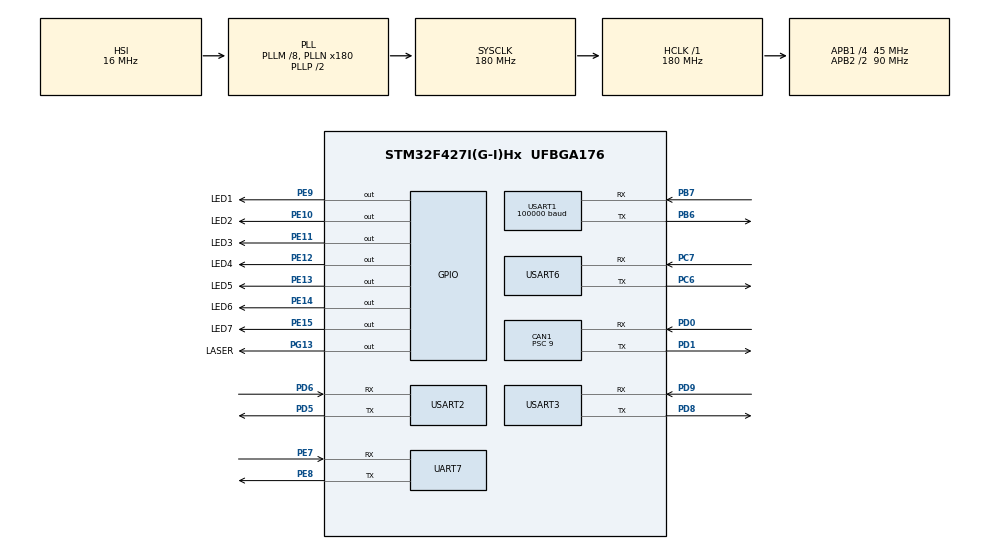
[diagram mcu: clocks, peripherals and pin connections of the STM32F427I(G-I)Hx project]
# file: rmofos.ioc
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CAN1.BS1=CAN_BS1_2TQ
CAN1.BS2=CAN_BS2_2TQ
CAN1.CalculateTimeQuantum=200.0
CAN1.Prescaler=9
CAN1.SJW=CAN_SJW_4TQ
Dma.Request0=USART6_RX
Dma.Request1=USART1_RX
Dma.USART1_RX.1.Direction=DMA_PERIPH_TO_MEMORY
Dma.USART1_RX.1.FIFOMode=DMA_FIFOMODE_DISABLE
Dma.USART1_RX.1.Instance=DMA2_Stream2
Dma.USART1_RX.1.MemDataAlignment=DMA_MDATAALIGN_BYTE
Dma.USART1_RX.1.MemInc=DMA_MINC_ENABLE
Dma.USART1_RX.1.Mode=DMA_NORMAL
Dma.USART1_RX.1.PeriphDataAlignment=DMA_PDATAALIGN_BYTE
Dma.USART1_RX.1.PeriphInc=DMA_PINC_DISABLE
Dma.USART1_RX.1.Priority=DMA_PRIORITY_HIGH
Dma.USART6_RX.0.Direction=DMA_PERIPH_TO_MEMORY
Dma.USART6_RX.0.FIFOMode=DMA_FIFOMODE_DISABLE
Dma.USART6_RX.0.Instance=DMA2_Stream1
Dma.USART6_RX.0.MemDataAlignment=DMA_MDATAALIGN_BYTE
Dma.USART6_RX.0.MemInc=DMA_MINC_ENABLE
Dma.USART6_RX.0.Mode=DMA_NORMAL
Dma.USART6_RX.0.PeriphDataAlignment=DMA_PDATAALIGN_BYTE
Dma.USART6_RX.0.PeriphInc=DMA_PINC_DISABLE
Dma.USART6_RX.0.Priority=DMA_PRIORITY_MEDIUM
FREERTOS.Tasks01=defaultTask,0,128,StartDefaultTask,Default,NULL
FREERTOS.configGENERATE_RUN_TIME_STATS=1
FREERTOS.configTOTAL_HEAP_SIZE=17408
FREERTOS.configUSE_STATS_FORMATTING_FUNCTIONS=1
FREERTOS.configUSE_TRACE_FACILITY=1
Mcu.Family=STM32F4
Mcu.Name=STM32F427I(G-I)Hx
Mcu.Package=UFBGA176
NVIC.CAN1_RX0_IRQn=true\:6\:0\:true\:false\:true\:true\:true
NVIC.DMA2_Stream1_IRQn=true\:5\:0\:false\:false\:true\:true\:false
NVIC.DMA2_Stream2_IRQn=true\:5\:0\:false\:false\:true\:true\:false
NVIC.PriorityGroup=NVIC_PRIORITYGROUP_4
NVIC.TIM8_UP_TIM13_IRQn=true\:0\:0\:false\:false\:true\:false\:false
NVIC.TimeBase=TIM8_UP_TIM13_IRQn
NVIC.TimeBaseIP=TIM8
NVIC.USART1_IRQn=true\:5\:0\:false\:false\:true\:true\:true
NVIC.USART3_IRQn=true\:6\:0\:true\:false\:true\:true\:true
NVIC.USART6_IRQn=true\:6\:0\:true\:false\:true\:true\:true
PA13.Mode=Serial_Wire
PA13.Signal=SYS_JTMS-SWDIO
PA14.Mode=Serial_Wire
PA14.Signal=SYS_JTCK-SWCLK
PB6.Mode=Asynchronous
PB6.Signal=USART1_TX
PB7.Mode=Asynchronous
PB7.Signal=USART1_RX
PC6.Mode=Asynchronous
PC6.Signal=USART6_TX
PC7.Mode=Asynchronous
PC7.Signal=USART6_RX
PD0.GPIO_PuPd=GPIO_PULLUP
PD0.Mode=Master
PD0.Signal=CAN1_RX
PD1.GPIO_PuPd=GPIO_PULLUP
PD1.Mode=Master
PD1.Signal=CAN1_TX
PD5.Mode=Asynchronous
PD5.Signal=USART2_TX
PD6.Mode=Asynchronous
PD6.Signal=USART2_RX
PD8.Mode=Asynchronous
PD8.Signal=USART3_TX
PD9.Mode=Asynchronous
PD9.Signal=USART3_RX
PE10.GPIO_Label=LED2
PE10.PinState=GPIO_PIN_SET
PE10.Signal=GPIO_Output
PE11.GPIO_Label=LED3
PE11.PinState=GPIO_PIN_SET
PE11.Signal=GPIO_Output
PE12.GPIO_Label=LED4
PE12.PinState=GPIO_PIN_SET
PE12.Signal=GPIO_Output
PE13.GPIO_Label=LED5
PE13.PinState=GPIO_PIN_SET
PE13.Signal=GPIO_Output
PE14.GPIO_Label=LED6
PE14.PinState=GPIO_PIN_SET
PE14.Signal=GPIO_Output
PE15.GPIO_Label=LED7
PE15.PinState=GPIO_PIN_SET
PE15.Signal=GPIO_Output
PE7.Mode=Asynchronous
PE7.Signal=UART7_RX
PE8.Mode=Asynchronous
PE8.Signal=UART7_TX
PE9.GPIO_Label=LED1
PE9.PinState=GPIO_PIN_SET
PE9.Signal=GPIO_Output
PG13.GPIO_Label=LASER
PG13.PinState=GPIO_PIN_SET
PG13.Signal=GPIO_Output
PH0/OSC_IN.Mode=HSE-External-Oscillator
PH0/OSC_IN.Signal=RCC_OSC_IN
PH1/OSC_OUT.Mode=HSE-External-Oscillator
PH1/OSC_OUT.Signal=RCC_OSC_OUT
ProjectManager.HeapSize=0x200
ProjectManager.StackSize=0x400
ProjectManager.TargetToolchain=MDK-ARM V5
RCC.48MHZClocksFreq_Value=90000000
RCC.AHBFreq_Value=180000000
RCC.APB1CLKDivider=RCC_HCLK_DIV4
RCC.APB1Freq_Value=45000000
RCC.APB1TimFreq_Value=90000000
RCC.APB2CLKDivider=RCC_HCLK_DIV2
RCC.APB2Freq_Value=90000000
RCC.APB2TimFreq_Value=180000000
RCC.CortexFreq_Value=180000000
RCC.HCLKFreq_Value=180000000
RCC.HSE_VALUE=12000000
RCC.HSI_VALUE=16000000
RCC.LSE_VALUE=32768
RCC.PLLM=8
RCC.PLLN=180
RCC.SYSCLKFreq_VALUE=180000000
RCC.SYSCLKSource=RCC_SYSCLKSOURCE_PLLCLK
RCC.VCOOutputFreq_Value=360000000
TIM3.Period=9999
TIM3.Prescaler=89
UART7.VirtualMode=Asynchronous
USART1.BaudRate=100000
USART1.Parity=PARITY_EVEN
USART1.VirtualMode=VM_ASYNC
USART2.VirtualMode=VM_ASYNC
USART3.VirtualMode=VM_ASYNC
USART6.VirtualMode=VM_ASYNC
VP_FREERTOS_VS_ENABLE.Mode=Enabled
VP_SYS_VS_tim8.Mode=TIM8
VP_TIM3_VS_ClockSourceINT.Mode=Internal
board=custom

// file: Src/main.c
/**
  ******************************************************************************
  * @file           : main.c
  * @brief          : Main program body
  ******************************************************************************
  * This notice applies to any and all portions of this file
  * that are not between comment pairs USER CODE BEGIN and
  * USER CODE END. Other portions of this file, whether
  * inserted by the user or by software development tools
  * are owned by their respective copyright owners.
  *
  * Copyright (c) 2019 STMicroelectronics International N.V.
  * All rights reserved.
  *
  * Redistribution and use in source and binary forms, with or without
  * modification, are permitted, provided that the following conditions are met:
  *
  * 1. Redistribution of source code must retain the above copyright notice,
  *    this list of conditions and the following disclaimer.
  * 2. Redistributions in binary form must reproduce the above copyright notice,
  *    this list of conditions and the following disclaimer in the documentation
  *    and/or other materials provided with the distribution.
  * 3. Neither the name of STMicroelectronics nor the names of other
  *    contributors to this software may be used to endorse or promote products
  *    derived from this software without specific written permission.
  * 4. This software, including modifications and/or derivative works of this
  *    software, must execute solely and exclusively on microcontroller or
  *    microprocessor devices manufactured by or for STMicroelectronics.
  * 5. Redistribution and use of this software other than as permitted under
  *    this license is void and will automatically terminate your rights under
  *    this license.
  *
  * THIS SOFTWARE IS PROVIDED BY STMICROELECTRONICS AND CONTRIBUTORS "AS IS"
  * AND ANY EXPRESS, IMPLIED OR STATUTORY WARRANTIES, INCLUDING, BUT NOT
  * LIMITED TO, THE IMPLIED WARRANTIES OF MERCHANTABILITY, FITNESS FOR A
  * PARTICULAR PURPOSE AND NON-INFRINGEMENT OF THIRD PARTY INTELLECTUAL PROPERTY
  * RIGHTS ARE DISCLAIMED TO THE FULLEST EXTENT PERMITTED BY LAW. IN NO EVENT
  * SHALL STMICROELECTRONICS OR CONTRIBUTORS BE LIABLE FOR ANY DIRECT, INDIRECT,
  * INCIDENTAL, SPECIAL, EXEMPLARY, OR CONSEQUENTIAL DAMAGES (INCLUDING, BUT NOT
  * LIMITED TO, PROCUREMENT OF SUBSTITUTE GOODS OR SERVICES; LOSS OF USE, DATA,
  * OR PROFITS; OR BUSINESS INTERRUPTION) HOWEVER CAUSED AND ON ANY THEORY OF
  * LIABILITY, WHETHER IN CONTRACT, STRICT LIABILITY, OR TORT (INCLUDING
  * NEGLIGENCE OR OTHERWISE) ARISING IN ANY WAY OUT OF THE USE OF THIS SOFTWARE,
  * EVEN IF ADVISED OF THE POSSIBILITY OF SUCH DAMAGE.
  *
  ******************************************************************************
  */
#include "main.h"
#include "stm32f4xx_hal.h"
#include "cmsis_os.h"

/* USER CODE BEGIN Includes */
#include "user.h"
/* USER CODE END Includes */

CAN_HandleTypeDef hcan1;

TIM_HandleTypeDef htim3;

UART_HandleTypeDef huart7;
UART_HandleTypeDef huart1;
UART_HandleTypeDef huart2;
UART_HandleTypeDef huart3;
UART_HandleTypeDef huart6;
DMA_HandleTypeDef hdma_usart1_rx;
DMA_HandleTypeDef hdma_usart6_rx;

osThreadId defaultTaskHandle;

/* USER CODE BEGIN PV */
/* Private variables ---------------------------------------------------------*/

/* USER CODE END PV */

void SystemClock_Config(void);
static void MX_GPIO_Init(void);
static void MX_DMA_Init(void);
static void MX_CAN1_Init(void);
static void MX_USART1_UART_Init(void);
static void MX_USART2_UART_Init(void);
static void MX_USART3_UART_Init(void);
static void MX_USART6_UART_Init(void);
static void MX_TIM3_Init(void);
static void MX_UART7_Init(void);
void StartDefaultTask(void const * argument);

/* USER CODE BEGIN PFP */
/* Private function prototypes -----------------------------------------------*/

/* USER CODE END PFP */

int main(void)
{

  /* MCU Configuration----------------------------------------------------------*/

  /* Reset of all peripherals, Initializes the Flash interface and the Systick. */
  HAL_Init();

  /* Configure the system clock */
  SystemClock_Config();

  /* Initialize all configured peripherals */
  MX_GPIO_Init();
  MX_DMA_Init();
  MX_CAN1_Init();
  MX_USART1_UART_Init();
  MX_USART2_UART_Init();
  MX_USART3_UART_Init();
  MX_USART6_UART_Init();
  MX_TIM3_Init();
  MX_UART7_Init();
  /* USER CODE BEGIN 2 */
      SysInit();//系统初始化
  /* USER CODE END 2 */

  /* Create the thread(s) */
  /* definition and creation of defaultTask */
  osThreadDef(defaultTask, StartDefaultTask, osPriorityNormal, 0, 128);
  defaultTaskHandle = osThreadCreate(osThread(defaultTask), NULL);

  /* Start scheduler */
  osKernelStart();

  /* We should never get here as control is now taken by the scheduler */

  /* Infinite loop */
  while (1)
  {

  }

}

void SystemClock_Config(void)
{

  RCC_OscInitTypeDef RCC_OscInitStruct;
  RCC_ClkInitTypeDef RCC_ClkInitStruct;

    /**Configure the main internal regulator output voltage
    */
  __HAL_RCC_PWR_CLK_ENABLE();

  __HAL_PWR_VOLTAGESCALING_CONFIG(PWR_REGULATOR_VOLTAGE_SCALE1);

    /**Initializes the CPU, AHB and APB busses clocks
    */
  RCC_OscInitStruct.OscillatorType = RCC_OSCILLATORTYPE_HSI;
  RCC_OscInitStruct.HSIState = RCC_HSI_ON;
  RCC_OscInitStruct.HSICalibrationValue = 16;
  RCC_OscInitStruct.PLL.PLLState = RCC_PLL_ON;
  RCC_OscInitStruct.PLL.PLLSource = RCC_PLLSOURCE_HSI;
  RCC_OscInitStruct.PLL.PLLM = 8;
  RCC_OscInitStruct.PLL.PLLN = 180;
  RCC_OscInitStruct.PLL.PLLP = RCC_PLLP_DIV2;
  RCC_OscInitStruct.PLL.PLLQ = 4;
  if (HAL_RCC_OscConfig(&RCC_OscInitStruct) != HAL_OK)
  {
    _Error_Handler(__FILE__, __LINE__);
  }

    /**Activate the Over-Drive mode
    */
  if (HAL_PWREx_EnableOverDrive() != HAL_OK)
  {
    _Error_Handler(__FILE__, __LINE__);
  }

    /**Initializes the CPU, AHB and APB busses clocks
    */
  RCC_ClkInitStruct.ClockType = RCC_CLOCKTYPE_HCLK|RCC_CLOCKTYPE_SYSCLK
                              |RCC_CLOCKTYPE_PCLK1|RCC_CLOCKTYPE_PCLK2;
  RCC_ClkInitStruct.SYSCLKSource = RCC_SYSCLKSOURCE_PLLCLK;
  RCC_ClkInitStruct.AHBCLKDivider = RCC_SYSCLK_DIV1;
  RCC_ClkInitStruct.APB1CLKDivider = RCC_HCLK_DIV4;
  RCC_ClkInitStruct.APB2CLKDivider = RCC_HCLK_DIV2;

  if (HAL_RCC_ClockConfig(&RCC_ClkInitStruct, FLASH_LATENCY_5) != HAL_OK)
  {
    _Error_Handler(__FILE__, __LINE__);
  }

    /**Configure the Systick interrupt time
    */
  HAL_SYSTICK_Config(HAL_RCC_GetHCLKFreq()/1000);

    /**Configure the Systick
    */
  HAL_SYSTICK_CLKSourceConfig(SYSTICK_CLKSOURCE_HCLK);

  /* SysTick_IRQn interrupt configuration */
  HAL_NVIC_SetPriority(SysTick_IRQn, 15, 0);
}

/* CAN1 init function */
static void MX_CAN1_Init(void)
{

  hcan1.Instance = CAN1;
  hcan1.Init.Prescaler = 9;
  hcan1.Init.Mode = CAN_MODE_NORMAL;
  hcan1.Init.SyncJumpWidth = CAN_SJW_4TQ;
  hcan1.Init.TimeSeg1 = CAN_BS1_2TQ;
  hcan1.Init.TimeSeg2 = CAN_BS2_2TQ;
  hcan1.Init.TimeTriggeredMode = DISABLE;
  hcan1.Init.AutoBusOff = DISABLE;
  hcan1.Init.AutoWakeUp = DISABLE;
  hcan1.Init.AutoRetransmission = DISABLE;
  hcan1.Init.ReceiveFifoLocked = DISABLE;
  hcan1.Init.TransmitFifoPriority = DISABLE;
  if (HAL_CAN_Init(&hcan1) != HAL_OK)
  {
    _Error_Handler(__FILE__, __LINE__);
  }

}

/* TIM3 init function */
static void MX_TIM3_Init(void)
{

  TIM_ClockConfigTypeDef sClockSourceConfig;
  TIM_MasterConfigTypeDef sMasterConfig;

  htim3.Instance = TIM3;
  htim3.Init.Prescaler = 89;
  htim3.Init.CounterMode = TIM_COUNTERMODE_UP;
  htim3.Init.Period = 9999;
  htim3.Init.ClockDivision = TIM_CLOCKDIVISION_DIV1;
  if (HAL_TIM_Base_Init(&htim3) != HAL_OK)
  {
    _Error_Handler(__FILE__, __LINE__);
  }

  sClockSourceConfig.ClockSource = TIM_CLOCKSOURCE_INTERNAL;
  if (HAL_TIM_ConfigClockSource(&htim3, &sClockSourceConfig) != HAL_OK)
  {
    _Error_Handler(__FILE__, __LINE__);
  }

  sMasterConfig.MasterOutputTrigger = TIM_TRGO_RESET;
  sMasterConfig.MasterSlaveMode = TIM_MASTERSLAVEMODE_DISABLE;
  if (HAL_TIMEx_MasterConfigSynchronization(&htim3, &sMasterConfig) != HAL_OK)
  {
    _Error_Handler(__FILE__, __LINE__);
  }

}

/* UART7 init function */
static void MX_UART7_Init(void)
{

  huart7.Instance = UART7;
  huart7.Init.BaudRate = 115200;
  huart7.Init.WordLength = UART_WORDLENGTH_8B;
  huart7.Init.StopBits = UART_STOPBITS_1;
  huart7.Init.Parity = UART_PARITY_NONE;
  huart7.Init.Mode = UART_MODE_TX_RX;
  huart7.Init.HwFlowCtl = UART_HWCONTROL_NONE;
  huart7.Init.OverSampling = UART_OVERSAMPLING_16;
  if (HAL_UART_Init(&huart7) != HAL_OK)
  {
    _Error_Handler(__FILE__, __LINE__);
  }

}

/* USART1 init function */
static void MX_USART1_UART_Init(void)
{

  huart1.Instance = USART1;
  huart1.Init.BaudRate = 100000;
  huart1.Init.WordLength = UART_WORDLENGTH_8B;
  huart1.Init.StopBits = UART_STOPBITS_1;
  huart1.Init.Parity = UART_PARITY_EVEN;
  huart1.Init.Mode = UART_MODE_TX_RX;
  huart1.Init.HwFlowCtl = UART_HWCONTROL_NONE;
  huart1.Init.OverSampling = UART_OVERSAMPLING_16;
  if (HAL_UART_Init(&huart1) != HAL_OK)
  {
    _Error_Handler(__FILE__, __LINE__);
  }

}

/* USART2 init function */
static void MX_USART2_UART_Init(void)
{

  huart2.Instance = USART2;
  huart2.Init.BaudRate = 115200;
  huart2.Init.WordLength = UART_WORDLENGTH_8B;
  huart2.Init.StopBits = UART_STOPBITS_1;
  huart2.Init.Parity = UART_PARITY_NONE;
  huart2.Init.Mode = UART_MODE_TX_RX;
  huart2.Init.HwFlowCtl = UART_HWCONTROL_NONE;
  huart2.Init.OverSampling = UART_OVERSAMPLING_16;
  if (HAL_UART_Init(&huart2) != HAL_OK)
  {
    _Error_Handler(__FILE__, __LINE__);
  }

}

/* USART3 init function */
static void MX_USART3_UART_Init(void)
{

  huart3.Instance = USART3;
  huart3.Init.BaudRate = 115200;
  huart3.Init.WordLength = UART_WORDLENGTH_8B;
  huart3.Init.StopBits = UART_STOPBITS_1;
  huart3.Init.Parity = UART_PARITY_NONE;
  huart3.Init.Mode = UART_MODE_TX_RX;
  huart3.Init.HwFlowCtl = UART_HWCONTROL_NONE;
  huart3.Init.OverSampling = UART_OVERSAMPLING_16;
  if (HAL_UART_Init(&huart3) != HAL_OK)
  {
    _Error_Handler(__FILE__, __LINE__);
  }

}

/* USART6 init function */
static void MX_USART6_UART_Init(void)
{

  huart6.Instance = USART6;
  huart6.Init.BaudRate = 115200;
  huart6.Init.WordLength = UART_WORDLENGTH_8B;
  huart6.Init.StopBits = UART_STOPBITS_1;
  huart6.Init.Parity = UART_PARITY_NONE;
  huart6.Init.Mode = UART_MODE_TX_RX;
  huart6.Init.HwFlowCtl = UART_HWCONTROL_NONE;
  huart6.Init.OverSampling = UART_OVERSAMPLING_16;
  if (HAL_UART_Init(&huart6) != HAL_OK)
  {
    _Error_Handler(__FILE__, __LINE__);
  }

}

static void MX_DMA_Init(void)
{
  /* DMA controller clock enable */
  __HAL_RCC_DMA2_CLK_ENABLE();

  /* DMA interrupt init */
  /* DMA2_Stream1_IRQn interrupt configuration */
  HAL_NVIC_SetPriority(DMA2_Stream1_IRQn, 5, 0);
  HAL_NVIC_EnableIRQ(DMA2_Stream1_IRQn);
  /* DMA2_Stream2_IRQn interrupt configuration */
  HAL_NVIC_SetPriority(DMA2_Stream2_IRQn, 5, 0);
  HAL_NVIC_EnableIRQ(DMA2_Stream2_IRQn);

}

/** Configure pins as
        * Analog
        * Input
        * Output
        * EVENT_OUT
        * EXTI
*/
static void MX_GPIO_Init(void)
{

  GPIO_InitTypeDef GPIO_InitStruct;

  /* GPIO Ports Clock Enable */
  __HAL_RCC_GPIOG_CLK_ENABLE();
  __HAL_RCC_GPIOA_CLK_ENABLE();
  __HAL_RCC_GPIOB_CLK_ENABLE();
  __HAL_RCC_GPIOD_CLK_ENABLE();
  __HAL_RCC_GPIOH_CLK_ENABLE();
  __HAL_RCC_GPIOC_CLK_ENABLE();
  __HAL_RCC_GPIOE_CLK_ENABLE();

  /*Configure GPIO pin Output Level */
  HAL_GPIO_WritePin(LASER_GPIO_Port, LASER_Pin, GPIO_PIN_SET);

  /*Configure GPIO pin Output Level */
  HAL_GPIO_WritePin(GPIOE, LED5_Pin|LED1_Pin|LED3_Pin|LED6_Pin
                          |LED2_Pin|LED4_Pin|LED7_Pin, GPIO_PIN_SET);

  /*Configure GPIO pin : LASER_Pin */
  GPIO_InitStruct.Pin = LASER_Pin;
  GPIO_InitStruct.Mode = GPIO_MODE_OUTPUT_PP;
  GPIO_InitStruct.Pull = GPIO_NOPULL;
  GPIO_InitStruct.Speed = GPIO_SPEED_FREQ_LOW;
  HAL_GPIO_Init(LASER_GPIO_Port, &GPIO_InitStruct);

  /*Configure GPIO pins : LED5_Pin LED1_Pin LED3_Pin LED6_Pin
                           LED2_Pin LED4_Pin LED7_Pin */
  GPIO_InitStruct.Pin = LED5_Pin|LED1_Pin|LED3_Pin|LED6_Pin
                          |LED2_Pin|LED4_Pin|LED7_Pin;
  GPIO_InitStruct.Mode = GPIO_MODE_OUTPUT_PP;
  GPIO_InitStruct.Pull = GPIO_NOPULL;
  GPIO_InitStruct.Speed = GPIO_SPEED_FREQ_LOW;
  HAL_GPIO_Init(GPIOE, &GPIO_InitStruct);

}

void StartDefaultTask(void const * argument)
{

  /* USER CODE BEGIN 5 */
//  	UserIOInit();
  /* Infinite loop */
  for(;;)
  {
    osDelay(100);
  }
//	vTaskDelete(defaultTaskHandle);
  /* USER CODE END 5 */
}

void HAL_TIM_PeriodElapsedCallback(TIM_HandleTypeDef *htim)
{
  if (htim->Instance == TIM8) {
    HAL_IncTick();
  }
}

void _Error_Handler(char *file, int line)
{
  while(1)
  {
  }
}

/************************ (C) COPYRIGHT STMicroelectronics *****END OF FILE****/
